AUTOSAR XML (schema 00050)
standard types defined: boolean, dtRef_const_VOID, dtRef_VOID, float32, sint16, sint8, uint16, uint32, uint64, uint8, boolean_CompuMethod, boolean_DataConstr, float32_DataConstr, sint16_DataConstr, sint8_DataConstr, uint16_DataConstr, uint8_DataConstr
package /ComponentTypes
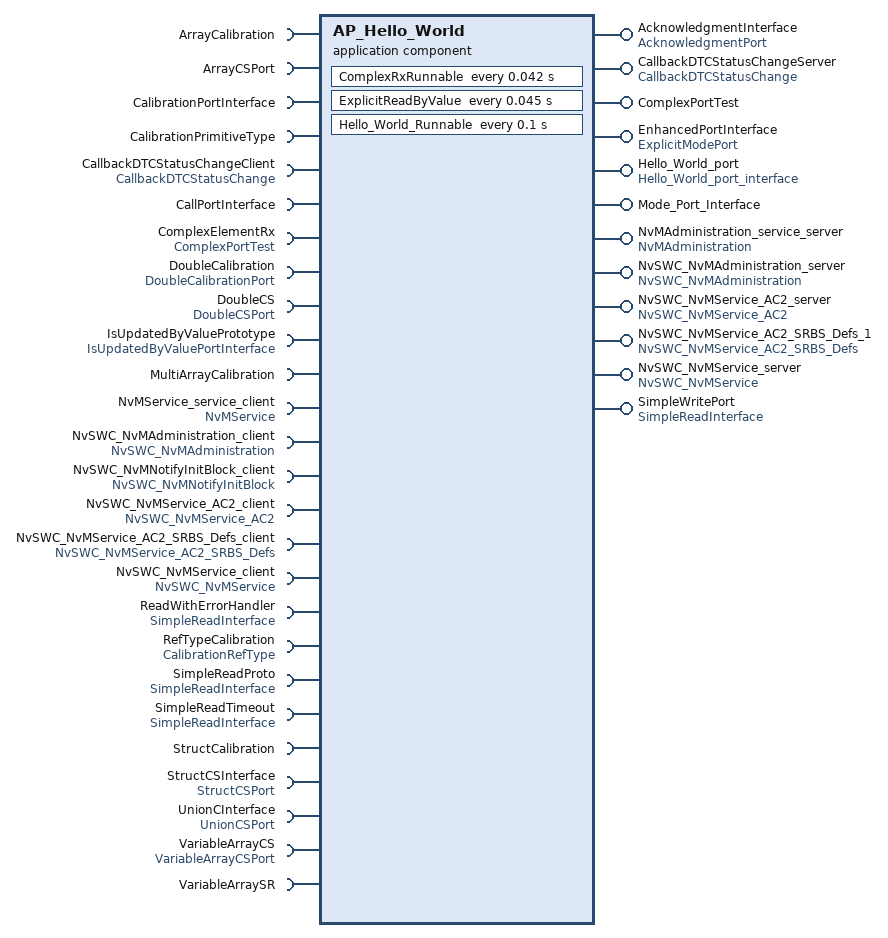
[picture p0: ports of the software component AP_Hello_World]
  application sw component type AP_Hello_World
    12 x provide port:
      AcknowledgmentInterface: provided-interface=AcknowledgmentPort
        provided-com-specs:
          data-element=nonWaitElement, transmission-acknowledge=timeout=0
          data-element=waitElement, transmission-acknowledge=timeout=0
      CallbackDTCStatusChangeServer: server-com-spec{operation=DTCStatusChanged, queue-length=1, end-to-end-transformation-com-spec-props=disable-end-to-end-check=false}, provided-interface=CallbackDTCStatusChange
      ComplexPortTest: provided-interface=ComplexPortTest
        provided-com-specs:
          queued-sender-com-spec={data-element=QueuedElement, transmission-acknowledge=timeout=2}
          nonqueued-sender-com-spec=data-element=ArrayOfTypeRefElement
          nonqueued-sender-com-spec={data-element=ComplexElement, transmission-acknowledge=timeout=2}
          nonqueued-sender-com-spec=data-element=ConstrainedElement
          nonqueued-sender-com-spec=data-element=HandleInvalidElement
      EnhancedPortInterface: mode-switch-sender-com-spec{enhanced-mode-api=true, mode-group=Mode, queue-length=1}, provided-interface=ExplicitModePort
      Hello_World_port: nonqueued-sender-com-spec{data-element=Hello_World_Element, init-value=0}, provided-interface=Hello_World_port_interface
      Mode_Port_Interface: mode-switch-sender-com-spec{enhanced-mode-api=false, mode-group=ModeGroup, mode-switched-ack=timeout=42, queue-length=123}, provided-interface=Mode_Port_Interface
      NvMAdministration_service_server: server-com-spec{operation=NvMAdministration/SetBlockProtection, queue-length=1}, provided-interface=NvMAdministration
      NvSWC_NvMAdministration_server: server-com-spec{operation=NvSWC_NvMAdministration/SetBlockProtection, queue-length=1}, provided-interface=NvSWC_NvMAdministration
      NvSWC_NvMService_AC2_server: provided-interface=NvSWC_NvMService_AC2
        provided-com-specs:
          operation=NvSWC_NvMService_AC2/GetErrorStatus, queue-length=1
          operation=NvSWC_NvMService_AC2/ReadBlock, queue-length=1
          operation=NvSWC_NvMService_AC2/WriteBlock, queue-length=10
      NvSWC_NvMService_AC2_SRBS_Defs_1: provided-interface=NvSWC_NvMService_AC2_SRBS_Defs
        provided-com-specs:
          operation=NvSWC_NvMService_AC2_SRBS_Defs/GetErrorStatus, queue-length=1
          operation=NvSWC_NvMService_AC2_SRBS_Defs/ReadBlock, queue-length=1
          operation=RestoreBlockDefaults, queue-length=1
          operation=SetRamBlockStatus, queue-length=1
          operation=NvSWC_NvMService_AC2_SRBS_Defs/WriteBlock, queue-length=1
      NvSWC_NvMService_server: server-com-spec{operation=NvSWC_NvMService/GetErrorStatus, queue-length=1}, provided-interface=NvSWC_NvMService
      SimpleWritePort: provided-interface=SimpleReadInterface
        provided-com-specs:
          data-element=ReadElementOpenRange
          data-element=ReadElementRangeInfMax
          data-element=SimpleReadElement
          data-element=SimpleReadNeverReceived
    10 x provide/require port:
      ArraySRInterface: provided-required-interface=ArraySRPort
        provided-com-specs:
          data-element=acknowlegdement, transmission-acknowledge=timeout=0
          data-element=constraint
          data-element=errorHandling
          data-element=handleKeep
          data-element=Iconstraint
          data-element=init, init-value=[0, 10, 20, 30, 40, 50, 60, 70, 80, 90]
          data-element=initConstraint, init-value=[1, 2, 3, 4, 5, 6, 7, 8, 9, 10]
          data-element=INone
        required-com-specs:
          data-element=acknowlegdement, filter=data-filter-type=ALWAYS
          data-element=constraint, filter=data-filter-type=ALWAYS
          data-element=errorHandling, filter=data-filter-type=ALWAYS
          data-element=handleKeep, filter=data-filter-type=ALWAYS
          data-element=Iconstraint, filter=data-filter-type=ALWAYS
          data-element=init, filter=data-filter-type=ALWAYS
          data-element=initConstraint, filter=data-filter-type=ALWAYS
          data-element=INone, filter=data-filter-type=ALWAYS
      BooleanSR: nonqueued-sender-com-spec=data-element=isElement, nonqueued-receiver-com-spec{data-element=isElement, filter=data-filter-type=ALWAYS}, provided-required-interface=BooleanSRPort
      DataConstraintInterface: provided-required-interface=DataConstraintPort
        provided-com-specs:
          data-element=AllConstr
          data-element=ApplicationTypeAllConstr
          data-element=ApplicationTypeConstr
          data-element=ApplicationTypeImplConstr
          data-element=DataProtypeApplConstr
          data-element=DataProtypeConstr
          data-element=DataProtypeImplConstr
          data-element=ImplementationTypeConstr
          data-element=InfFloatConstr
          data-element=NoConstr
        required-com-specs:
          data-element=AllConstr, filter=data-filter-type=ALWAYS
          data-element=ApplicationTypeAllConstr, filter=data-filter-type=ALWAYS
          data-element=ApplicationTypeConstr, filter=data-filter-type=ALWAYS
          data-element=ApplicationTypeImplConstr, filter=data-filter-type=ALWAYS
          data-element=DataProtypeApplConstr, filter=data-filter-type=ALWAYS
          data-element=DataProtypeConstr, filter=data-filter-type=ALWAYS
          data-element=DataProtypeImplConstr, filter=data-filter-type=ALWAYS
          data-element=ImplementationTypeConstr, filter=data-filter-type=ALWAYS
          data-element=InfFloatConstr
          data-element=NoConstr, filter=data-filter-type=ALWAYS
      DoubleSRPort: provided-com-specs=[data-element=DoubleSRPort/explicitElem, data-element=DoubleSRPort/implicitElem], provided-required-interface=DoubleSRPort
        required-com-specs:
          data-element=DoubleSRPort/explicitElem, filter=data-filter-type=ALWAYS
          data-element=DoubleSRPort/implicitElem, filter=data-filter-type=ALWAYS
      MultiArraySRInterface: provided-com-specs=[data-element=multiArray, data-element=multiArrayConstraint, data-element=multiArrayConstraintImplicit], provided-required-interface=MultiArraySRPort
        required-com-specs:
          data-element=multiArray, filter=data-filter-type=ALWAYS
          data-element=multiArrayConstraint, filter=data-filter-type=ALWAYS
          data-element=multiArrayConstraintImplicit, filter=data-filter-type=ALWAYS
      SimpleNvDataPort: nv-provide-com-spec=element_OneToTen, nv-require-com-spec=element_OneToTen, provided-required-interface=SimpleNvDataInterface
      StructSRInterface: provided-com-specs=[data-element=Element, data-element=IElement], provided-required-interface=StructSRPort
        required-com-specs:
          data-element=Element, filter=data-filter-type=ALWAYS
          data-element=IElement, filter=data-filter-type=ALWAYS
      TriggerInterface: provided-required-interface=SomeTriggerInterface
      TriggerInterfaceError: provided-required-interface=SomeTriggerInterface
      UnionSRInterface: provided-com-specs=[data-element=UnionSRPort/explicitElem, data-element=UnionSRPort/implicitElem], provided-required-interface=UnionSRPort
        required-com-specs:
          data-element=UnionSRPort/explicitElem, filter=data-filter-type=ALWAYS
          data-element=UnionSRPort/implicitElem, filter=data-filter-type=ALWAYS
    26 x require port:
      ArrayCalibration: required-com-specs=[arrayElement, variableArrayElem], required-interface=ArrayCalibration
      ArrayCSPort: required-com-specs=[ArrayCSPort/Operation, sumArray], required-interface=ArrayCSPort
      CalibrationPortInterface: parameter-require-com-spec{init-value=12342, parameter=CalibrationElement}, required-interface=CalibrationPortInterface
      CalibrationPrimitiveType: required-interface=CalibrationPrimitiveType
        required-com-specs:
          CalibrationPrimitiveType/notAccessibleElement
          CalibrationPrimitiveType/readOnlyElement
          CalibrationPrimitiveType/readWriteElement
      CallbackDTCStatusChangeClient: client-com-spec=DTCStatusChanged, required-interface=CallbackDTCStatusChange
      CallPortInterface: required-com-specs=[InOutOperation, SimpleIntOperation], required-interface=CallPortInterface
      ComplexElementRx: required-interface=ComplexPortTest
        required-com-specs:
          queued-receiver-com-spec={data-element=QueuedElement, queue-length=1}
          nonqueued-receiver-com-spec={data-element=ArrayOfTypeRefElement, filter=data-filter-type=ALWAYS, init-value=[rule-based-values={rule=FILL_UNTIL_END, rule-arguments=0}]}
          nonqueued-receiver-com-spec={data-element=ComplexElement, filter=data-filter-type=ALWAYS}
          nonqueued-receiver-com-spec={data-element=ConstrainedElement, filter=data-filter-type=ALWAYS}
          nonqueued-receiver-com-spec={data-element=HandleInvalidElement, filter=data-filter-type=ALWAYS}
      DoubleCalibration: parameter-require-com-spec=doubleElem, required-interface=DoubleCalibrationPort
      DoubleCS: client-com-spec=DoubleCSPort/f, required-interface=DoubleCSPort
      IsUpdatedByValuePrototype: required-interface=IsUpdatedByValuePortInterface
        required-com-specs:
          data-element=IdUpdatedByValueElement, enable-update=true, filter=data-filter-type=ALWAYS
          data-element=IsUpdatedByArgumentElement, enable-update=true, filter=data-filter-type=ALWAYS
      MultiArrayCalibration: parameter-require-com-spec=multiArrayElement, required-interface=MultiArrayCalibration
      NvMService_service_client: client-com-spec{operation=NvMService/GetErrorStatus, end-to-end-transformation-com-spec-props{disable-end-to-end-check=false, max-delta-counter=1, max-error-state-init=3, max-error-state-invalid=5, max-error-state-valid=7, max-no-new-or-repeated-data=9, min-ok-state-init=2, min-ok-state-invalid=4, min-ok-state-valid=6, sync-counter-init=8, window-size=10}}, required-interface=NvMService
      NvSWC_NvMAdministration_client: client-com-spec=NvSWC_NvMAdministration/SetBlockProtection, required-interface=NvSWC_NvMAdministration
      NvSWC_NvMNotifyInitBlock_client: client-com-spec=InitBlock, required-interface=NvSWC_NvMNotifyInitBlock
      NvSWC_NvMService_AC2_client: required-interface=NvSWC_NvMService_AC2
        required-com-specs:
          operation=NvSWC_NvMService_AC2/GetErrorStatus, end-to-end-transformation-com-spec-props=disable-end-to-end-check=true
          {operation=NvSWC_NvMService_AC2/ReadBlock, end-to-end-transformation-com-spec-props{disable-end-to-end-check=false, max-delta-counter=1, max-error-state-init=3, max-error-state-invalid=5, max-error-state-valid=7, max-no-new-or-repeated-data=9, min-ok-state-init=2, min-ok-state-invalid=4, min-ok-state-valid=6, sync-counter-init=8, window-size=10}}
          NvSWC_NvMService_AC2/WriteBlock
      NvSWC_NvMService_AC2_SRBS_Defs_client: required-interface=NvSWC_NvMService_AC2_SRBS_Defs
        required-com-specs:
          NvSWC_NvMService_AC2_SRBS_Defs/GetErrorStatus
          NvSWC_NvMService_AC2_SRBS_Defs/ReadBlock
          RestoreBlockDefaults
          SetRamBlockStatus
          NvSWC_NvMService_AC2_SRBS_Defs/WriteBlock
      NvSWC_NvMService_client: client-com-spec=NvSWC_NvMService/GetErrorStatus, required-interface=NvSWC_NvMService
      ReadWithErrorHandler: required-interface=SimpleReadInterface
        required-com-specs:
          data-element=ReadElementOpenRange, filter=data-filter-type=ALWAYS
          data-element=ReadElementRangeInfMax, filter=data-filter-type=ALWAYS
          data-element=SimpleReadElement, filter=data-filter-type=ALWAYS
          data-element=SimpleReadNeverReceived, filter=data-filter-type=ALWAYS
      RefTypeCalibration: required-interface=CalibrationRefType
        required-com-specs:
          CalibrationRefType/notAccessibleElement
          CalibrationRefType/readOnlyElement
          CalibrationRefType/readWriteElement
      SimpleReadProto: required-interface=SimpleReadInterface
        required-com-specs:
          data-element=ReadElementOpenRange, filter=data-filter-type=ALWAYS
          data-element=ReadElementRangeInfMax, filter=data-filter-type=ALWAYS
          data-element=SimpleReadElement, filter=data-filter-type=ALWAYS, handle-never-received=true, init-value=12345
          data-element=SimpleReadNeverReceived, filter=data-filter-type=ALWAYS, handle-never-received=true
      SimpleReadTimeout: required-interface=SimpleReadInterface
        required-com-specs:
          data-element=ReadElementOpenRange, filter=data-filter-type=ALWAYS
          data-element=ReadElementRangeInfMax, filter=data-filter-type=ALWAYS
          data-element=SimpleReadElement, alive-timeout=3, filter=data-filter-type=ALWAYS
          data-element=SimpleReadNeverReceived, filter=data-filter-type=ALWAYS
      StructCalibration: parameter-require-com-spec=Element, required-interface=StructCalibration
      StructCSInterface: required-com-specs=[cloneStruct, StructCSPort/Operation], required-interface=StructCSPort
      UnionCInterface: client-com-spec=UnionCSPort/f, required-interface=UnionCSPort
      VariableArrayCS: client-com-spec=VariableArrayCSPort/f, required-interface=VariableArrayCSPort
      VariableArraySR: queued-receiver-com-spec{data-element=variableArrayConstr, queue-length=1}, required-interface=VariableArraySR
    behavior AP_Hello_World_InternalBehavior: data-type-mapping=[RecordMapping, CustomMap]
      exclusive area TestExclusiveArea
      ar-typed-per-instance-memorys:
        data PerInstanceMemory: sw-calibration-access=READ-ONLY, type=uint16
      data send completed event Event_WAIT_LOCAL_AcknowledgmentInterface_waitElement_SEND_AcknowledgmentInterface_waitElement: event-source=SEND_AcknowledgmentInterface_waitElement
      asynchronous server call returns event ASCRE_Hello_World_Runnable_AC_NvSWC_NvMService_client_GetErrorStatus: event-source=ASCRP_Hello_World_Runnable_AC_NvSWC_NvMService_client_GetErrorStatus
      mode switched ack event a9a433f4D5e4fD45a1Db829D577591972cd1: event-source=SWITCH_Mode_Port_Interface_ModeGroup
      4 x asynchronous server call returns event:
        ASCRE_NvSWC_NvMService_client_GetErrorStatus: event-source=ASCRP_NvSWC_NvMService_client_GetErrorStatus
        ASCRE_ServerCallRunnable_SC_NvSWC_NvMAdministration_client_SetBlockProtection: event-source=ASCRP_ServerCallRunnable_SC_NvSWC_NvMAdministration_client_SetBlockProtection
        ASCRE_ServiceRunnable_AC_NvSWC_NvMService_AC2_SRBS_Defs_client_SetRamBlockStatus: event-source=ASCRP_ServiceRunnable_AC_NvSWC_NvMService_AC2_SRBS_Defs_client_SetRamBlockStatus
        ASCRE_ServiceRunnable_SC_CallPortInterface_OtherIntOperation: event-source=ASCRP_ServiceRunnable_SC_CallPortInterface_OtherIntOperation
      timing event TMT_ComplexRxRunnable: start-on-event=ComplexRxRunnable, period=0.042
      timing event TMT_Runnable: start-on-event=ExplicitReadByValue, period=0.045
      timing event TMT_Hello_World_Runnable: start-on-event=Hello_World_Runnable, period=0.1
      external trigger occurred event EXTO_Hello_World_Runnable_TriggerInterface_SomeTriggerElement: start-on-event=Hello_World_Runnable, trigger=TriggerInterface.SomeTriggerElement
      external trigger occurred event EXTO_Hello_World_Runnable_TriggerInterfaceError_SomeTriggerElement: start-on-event=Hello_World_Runnable, trigger=TriggerInterfaceError.SomeTriggerElement
      4 x timing event:
        TMT_ImplicitReadRunnable: start-on-event=ImplicitReadRunnable, period=0.123
        TMT_0_MultipleInstanciationRunnable: start-on-event=MultipleInstanciationRunnable, period=0.132
        TMT_ReceiveRecordRunnable: start-on-event=ReceiveRecordRunnable, period=0.01
        TMT_ServerCallRunnable: start-on-event=ServiceRunnable, period=0.042
      explicit-inter-runnable-variables:
        data ExplicitInterRunnableStruct: type=ComplexStruct, init-value=fields=[intElement:0, floatElement:0, arrayElement:10 x 0, {short-label=structElement, fields=[boolElement:0, constrElement:0]}]
        data ExplicitInterRunnableValue: type=Uint8Constr, init-value=0
      implicit-inter-runnable-variables:
        data ImplicitInterRunnableStruct: type=ComplexStruct, init-value=fields=[intElement:0, floatElement:0, arrayElement:10 x 0, {short-label=structElement, fields=[boolElement:0, constrElement:0]}]
        data ImplicitInterRunnableValue: type=Uint8Constr, init-value=0
      per-instance-parameters:
        parameter data prototype PerInstanceInternalCalibrationParameter: sw-calibration-access=READ-ONLY, type=Uint8Constr
      port-api-options:
        enable-take-address=false, error-handling=NO-TRANSFORMER-ERROR-HANDLING, indirect-api=false, port=ArraySRInterface
        enable-take-address=false, error-handling=NO-TRANSFORMER-ERROR-HANDLING, indirect-api=false, port=CalibrationPortInterface
        enable-take-address=true, error-handling=NO-TRANSFORMER-ERROR-HANDLING, indirect-api=false, port=ComplexElementRx
        enable-take-address=false, error-handling=TRANSFORMER-ERROR-HANDLING, indirect-api=false, port=ComplexPortTest
        enable-take-address=false, error-handling=TRANSFORMER-ERROR-HANDLING, indirect-api=false, port=Hello_World_port
        enable-take-address=false, error-handling=NO-TRANSFORMER-ERROR-HANDLING, indirect-api=false, port=IsUpdatedByValuePrototype
        enable-take-address=false, error-handling=TRANSFORMER-ERROR-HANDLING, indirect-api=false, port=NvSWC_NvMNotifyInitBlock_client
        enable-take-address=false, error-handling=TRANSFORMER-ERROR-HANDLING, indirect-api=false, port=NvSWC_NvMService_AC2_client
        enable-take-address=false, error-handling=TRANSFORMER-ERROR-HANDLING, indirect-api=false, port=NvSWC_NvMService_AC2_SRBS_Defs_client
        enable-take-address=false, error-handling=NO-TRANSFORMER-ERROR-HANDLING, indirect-api=false, port=ReadWithErrorHandler
        enable-take-address=false, error-handling=NO-TRANSFORMER-ERROR-HANDLING, indirect-api=false, port=SimpleReadProto
        enable-take-address=false, error-handling=NO-TRANSFORMER-ERROR-HANDLING, indirect-api=false, port=SimpleWritePort
        enable-take-address=false, error-handling=TRANSFORMER-ERROR-HANDLING, indirect-api=false, port=TriggerInterfaceError
      22 x runnable:
        ArrayRunnable
          data-read-access:
            access READ_ArraySRInterface_Iconstraint: accessed-variable=ArraySRInterface.Iconstraint
            access READ_ArraySRInterface_INone: accessed-variable=ArraySRInterface.INone
          data-receive-point-by-arguments:
            6 x access:
              REC_ArraySRInterface_acknowlegdement: accessed-variable=ArraySRInterface.acknowlegdement
              REC_ArraySRInterface_constraint: accessed-variable=ArraySRInterface.constraint
              REC_ArraySRInterface_errorHandling: accessed-variable=ArraySRInterface.errorHandling
              REC_ArraySRInterface_handleKeep: accessed-variable=ArraySRInterface.handleKeep
              REC_ArraySRInterface_init: accessed-variable=ArraySRInterface.init
              REC_ArraySRInterface_initConstraint: accessed-variable=ArraySRInterface.initConstraint
          data-send-points:
            6 x access:
              SEND_ArraySRInterface_acknowlegdement: accessed-variable=ArraySRInterface.acknowlegdement
              SEND_ArraySRInterface_constraint: accessed-variable=ArraySRInterface.constraint
              SEND_ArraySRInterface_errorHandling: accessed-variable=ArraySRInterface.errorHandling
              SEND_ArraySRInterface_handleKeep: accessed-variable=ArraySRInterface.handleKeep
              SEND_ArraySRInterface_init: accessed-variable=ArraySRInterface.init
              SEND_ArraySRInterface_initConstraint: accessed-variable=ArraySRInterface.initConstraint
          data-write-access:
            access WRITE_ArraySRInterface_Iconstraint: accessed-variable=ArraySRInterface.Iconstraint
            access WRITE_ArraySRInterface_INone: accessed-variable=ArraySRInterface.INone
          14 x parameter access:
            PA_ArrayCalibration_arrayElement: accessed-parameter=ArrayCalibration.arrayElement
            PA_ArrayCalibration_variableArrayElem: accessed-parameter=ArrayCalibration.variableArrayElem
            PA_CalibrationPortInterface_CalibrationElement: accessed-parameter=CalibrationPortInterface.CalibrationElement
            PA_CalibrationPrimitiveType_notAccessibleElement: accessed-parameter=CalibrationPrimitiveType.notAccessibleElement
            PA_CalibrationPrimitiveType_readOnlyElement: accessed-parameter=CalibrationPrimitiveType.readOnlyElement
            PA_CalibrationPrimitiveType_readWriteElement: accessed-parameter=CalibrationPrimitiveType.readWriteElement
            PA_DoubleCalibration_doubleElem: accessed-parameter=DoubleCalibration.doubleElem
            PA_MultiArrayCalibration_multiArrayElement: accessed-parameter=MultiArrayCalibration.multiArrayElement
            PA_PerInstanceInternalCalibrationParameter: accessed-parameter=PerInstanceInternalCalibrationParameter
            PA_RefTypeCalibration_notAccessibleElement: accessed-parameter=RefTypeCalibration.notAccessibleElement
            PA_RefTypeCalibration_readOnlyElement: accessed-parameter=RefTypeCalibration.readOnlyElement
            PA_RefTypeCalibration_readWriteElement: accessed-parameter=RefTypeCalibration.readWriteElement
            PA_SharedInternalCalibrationParameter: accessed-parameter=SharedInternalCalibrationParameter
            PA_StructCalibration_Element: accessed-parameter=StructCalibration.Element
          sync call SC_ArrayCSPort_sumArray: operation=ArrayCSPort.sumArray, timeout=0
        BooleanRunnable
          data-receive-point-by-arguments:
            access REC_BooleanSR_isElement: accessed-variable=BooleanSR.isElement
          14 x parameter access:
            PA_ArrayCalibration_arrayElement: accessed-parameter=ArrayCalibration.arrayElement
            PA_ArrayCalibration_variableArrayElem: accessed-parameter=ArrayCalibration.variableArrayElem
            PA_CalibrationPortInterface_CalibrationElement: accessed-parameter=CalibrationPortInterface.CalibrationElement
            PA_CalibrationPrimitiveType_notAccessibleElement: accessed-parameter=CalibrationPrimitiveType.notAccessibleElement
            PA_CalibrationPrimitiveType_readOnlyElement: accessed-parameter=CalibrationPrimitiveType.readOnlyElement
            PA_CalibrationPrimitiveType_readWriteElement: accessed-parameter=CalibrationPrimitiveType.readWriteElement
            PA_DoubleCalibration_doubleElem: accessed-parameter=DoubleCalibration.doubleElem
            PA_MultiArrayCalibration_multiArrayElement: accessed-parameter=MultiArrayCalibration.multiArrayElement
            PA_PerInstanceInternalCalibrationParameter: accessed-parameter=PerInstanceInternalCalibrationParameter
            PA_RefTypeCalibration_notAccessibleElement: accessed-parameter=RefTypeCalibration.notAccessibleElement
            PA_RefTypeCalibration_readOnlyElement: accessed-parameter=RefTypeCalibration.readOnlyElement
            PA_RefTypeCalibration_readWriteElement: accessed-parameter=RefTypeCalibration.readWriteElement
            PA_SharedInternalCalibrationParameter: accessed-parameter=SharedInternalCalibrationParameter
            PA_StructCalibration_Element: accessed-parameter=StructCalibration.Element
        ComplexArrayRunnable
          data-read-access:
            access READ_MultiArraySRInterface_multiArrayConstraintImplicit: accessed-variable=MultiArraySRInterface.multiArrayConstraintImplicit
          data-receive-point-by-arguments:
            access REC_MultiArraySRInterface_multiArray: accessed-variable=MultiArraySRInterface.multiArray
            access REC_MultiArraySRInterface_multiArrayConstraint: accessed-variable=MultiArraySRInterface.multiArrayConstraint
          data-send-points:
            access SEND_MultiArraySRInterface_multiArray: accessed-variable=MultiArraySRInterface.multiArray
            access SEND_MultiArraySRInterface_multiArrayConstraint: accessed-variable=MultiArraySRInterface.multiArrayConstraint
          data-write-access:
            access WRITE_MultiArraySRInterface_multiArrayConstraintImplicit: accessed-variable=MultiArraySRInterface.multiArrayConstraintImplicit
          14 x parameter access:
            PA_ArrayCalibration_arrayElement: accessed-parameter=ArrayCalibration.arrayElement
            PA_ArrayCalibration_variableArrayElem: accessed-parameter=ArrayCalibration.variableArrayElem
            PA_CalibrationPortInterface_CalibrationElement: accessed-parameter=CalibrationPortInterface.CalibrationElement
            PA_CalibrationPrimitiveType_notAccessibleElement: accessed-parameter=CalibrationPrimitiveType.notAccessibleElement
            PA_CalibrationPrimitiveType_readOnlyElement: accessed-parameter=CalibrationPrimitiveType.readOnlyElement
            PA_CalibrationPrimitiveType_readWriteElement: accessed-parameter=CalibrationPrimitiveType.readWriteElement
            PA_DoubleCalibration_doubleElem: accessed-parameter=DoubleCalibration.doubleElem
            PA_MultiArrayCalibration_multiArrayElement: accessed-parameter=MultiArrayCalibration.multiArrayElement
            PA_PerInstanceInternalCalibrationParameter: accessed-parameter=PerInstanceInternalCalibrationParameter
            PA_RefTypeCalibration_notAccessibleElement: accessed-parameter=RefTypeCalibration.notAccessibleElement
            PA_RefTypeCalibration_readOnlyElement: accessed-parameter=RefTypeCalibration.readOnlyElement
            PA_RefTypeCalibration_readWriteElement: accessed-parameter=RefTypeCalibration.readWriteElement
            PA_SharedInternalCalibrationParameter: accessed-parameter=SharedInternalCalibrationParameter
            PA_StructCalibration_Element: accessed-parameter=StructCalibration.Element
        ComplexRxRunnable
          data-receive-point-by-arguments:
            4 x access:
              REC_ComplexElementRx_ComplexElement: accessed-variable=ComplexElementRx.ComplexElement
              REC_ComplexElementRx_ConstrainedElement: accessed-variable=ComplexElementRx.ConstrainedElement
              REC_ComplexElementRx_HandleInvalidElement: accessed-variable=ComplexElementRx.HandleInvalidElement
              REC_ComplexElementRx_QueuedElement: accessed-variable=ComplexElementRx.QueuedElement
          14 x parameter access:
            PA_ArrayCalibration_arrayElement: accessed-parameter=ArrayCalibration.arrayElement
            PA_ArrayCalibration_variableArrayElem: accessed-parameter=ArrayCalibration.variableArrayElem
            PA_CalibrationPortInterface_CalibrationElement: accessed-parameter=CalibrationPortInterface.CalibrationElement
            PA_CalibrationPrimitiveType_notAccessibleElement: accessed-parameter=CalibrationPrimitiveType.notAccessibleElement
            PA_CalibrationPrimitiveType_readOnlyElement: accessed-parameter=CalibrationPrimitiveType.readOnlyElement
            PA_CalibrationPrimitiveType_readWriteElement: accessed-parameter=CalibrationPrimitiveType.readWriteElement
            PA_DoubleCalibration_doubleElem: accessed-parameter=DoubleCalibration.doubleElem
            PA_MultiArrayCalibration_multiArrayElement: accessed-parameter=MultiArrayCalibration.multiArrayElement
            PA_PerInstanceInternalCalibrationParameter: accessed-parameter=PerInstanceInternalCalibrationParameter
            PA_RefTypeCalibration_notAccessibleElement: accessed-parameter=RefTypeCalibration.notAccessibleElement
            PA_RefTypeCalibration_readOnlyElement: accessed-parameter=RefTypeCalibration.readOnlyElement
            PA_RefTypeCalibration_readWriteElement: accessed-parameter=RefTypeCalibration.readWriteElement
            PA_SharedInternalCalibrationParameter: accessed-parameter=SharedInternalCalibrationParameter
            PA_StructCalibration_Element: accessed-parameter=StructCalibration.Element
        DataConstraintRunnable
          data-receive-point-by-arguments:
            10 x access:
              REC_DataConstraintInterface_AllConstr: accessed-variable=DataConstraintInterface.AllConstr
              REC_DataConstraintInterface_ApplicationTypeAllConstr: accessed-variable=DataConstraintInterface.ApplicationTypeAllConstr
              REC_DataConstraintInterface_ApplicationTypeConstr: accessed-variable=DataConstraintInterface.ApplicationTypeConstr
              REC_DataConstraintInterface_ApplicationTypeImplConstr: accessed-variable=DataConstraintInterface.ApplicationTypeImplConstr
              REC_DataConstraintInterface_DataProtypeApplConstr: accessed-variable=DataConstraintInterface.DataProtypeApplConstr
              REC_DataConstraintInterface_DataProtypeConstr: accessed-variable=DataConstraintInterface.DataProtypeConstr
              REC_DataConstraintInterface_DataProtypeImplConstr: accessed-variable=DataConstraintInterface.DataProtypeImplConstr
              REC_DataConstraintInterface_ImplementationTypeConstr: accessed-variable=DataConstraintInterface.ImplementationTypeConstr
              REC_DataConstraintInterface_InfFloatConstr: accessed-variable=DataConstraintInterface.InfFloatConstr
              REC_DataConstraintInterface_NoConstr: accessed-variable=DataConstraintInterface.NoConstr
          data-send-points:
            9 x access:
              SEND_DataConstraintInterface_AllConstr: accessed-variable=DataConstraintInterface.AllConstr
              SEND_DataConstraintInterface_ApplicationTypeAllConstr: accessed-variable=DataConstraintInterface.ApplicationTypeAllConstr
              SEND_DataConstraintInterface_ApplicationTypeConstr: accessed-variable=DataConstraintInterface.ApplicationTypeConstr
              SEND_DataConstraintInterface_ApplicationTypeImplConstr: accessed-variable=DataConstraintInterface.ApplicationTypeImplConstr
              SEND_DataConstraintInterface_DataProtypeApplConstr: accessed-variable=DataConstraintInterface.DataProtypeApplConstr
              SEND_DataConstraintInterface_DataProtypeConstr: accessed-variable=DataConstraintInterface.DataProtypeConstr
              SEND_DataConstraintInterface_DataProtypeImplConstr: accessed-variable=DataConstraintInterface.DataProtypeImplConstr
              SEND_DataConstraintInterface_ImplementationTypeConstr: accessed-variable=DataConstraintInterface.ImplementationTypeConstr
              SEND_DataConstraintInterface_NoConstr: accessed-variable=DataConstraintInterface.NoConstr
          14 x parameter access:
            PA_ArrayCalibration_arrayElement: accessed-parameter=ArrayCalibration.arrayElement
            PA_ArrayCalibration_variableArrayElem: accessed-parameter=ArrayCalibration.variableArrayElem
            PA_CalibrationPortInterface_CalibrationElement: accessed-parameter=CalibrationPortInterface.CalibrationElement
            PA_CalibrationPrimitiveType_notAccessibleElement: accessed-parameter=CalibrationPrimitiveType.notAccessibleElement
            PA_CalibrationPrimitiveType_readOnlyElement: accessed-parameter=CalibrationPrimitiveType.readOnlyElement
            PA_CalibrationPrimitiveType_readWriteElement: accessed-parameter=CalibrationPrimitiveType.readWriteElement
            PA_DoubleCalibration_doubleElem: accessed-parameter=DoubleCalibration.doubleElem
            PA_MultiArrayCalibration_multiArrayElement: accessed-parameter=MultiArrayCalibration.multiArrayElement
            PA_PerInstanceInternalCalibrationParameter: accessed-parameter=PerInstanceInternalCalibrationParameter
            PA_RefTypeCalibration_notAccessibleElement: accessed-parameter=RefTypeCalibration.notAccessibleElement
            PA_RefTypeCalibration_readOnlyElement: accessed-parameter=RefTypeCalibration.readOnlyElement
            PA_RefTypeCalibration_readWriteElement: accessed-parameter=RefTypeCalibration.readWriteElement
            PA_SharedInternalCalibrationParameter: accessed-parameter=SharedInternalCalibrationParameter
            PA_StructCalibration_Element: accessed-parameter=StructCalibration.Element
        DoubleRunnable
          data-read-access:
            access REC_DoubleSRPort_implicitElem: accessed-variable=DoubleSRPort.implicitElem
          data-receive-point-by-arguments:
            access REC_DoubleSRPort_explicitElem: accessed-variable=DoubleSRPort.explicitElem
          data-send-points:
            access SEND_DoubleSRPort_explicitElem: accessed-variable=DoubleSRPort.explicitElem
          data-write-access:
            access SEND_DoubleSRPort_implicitElem: accessed-variable=DoubleSRPort.implicitElem
          14 x parameter access:
            PA_ArrayCalibration_arrayElement: accessed-parameter=ArrayCalibration.arrayElement
            PA_ArrayCalibration_variableArrayElem: accessed-parameter=ArrayCalibration.variableArrayElem
            PA_CalibrationPortInterface_CalibrationElement: accessed-parameter=CalibrationPortInterface.CalibrationElement
            PA_CalibrationPrimitiveType_notAccessibleElement: accessed-parameter=CalibrationPrimitiveType.notAccessibleElement
            PA_CalibrationPrimitiveType_readOnlyElement: accessed-parameter=CalibrationPrimitiveType.readOnlyElement
            PA_CalibrationPrimitiveType_readWriteElement: accessed-parameter=CalibrationPrimitiveType.readWriteElement
            PA_DoubleCalibration_doubleElem: accessed-parameter=DoubleCalibration.doubleElem
            PA_MultiArrayCalibration_multiArrayElement: accessed-parameter=MultiArrayCalibration.multiArrayElement
            PA_PerInstanceInternalCalibrationParameter: accessed-parameter=PerInstanceInternalCalibrationParameter
            PA_RefTypeCalibration_notAccessibleElement: accessed-parameter=RefTypeCalibration.notAccessibleElement
            PA_RefTypeCalibration_readOnlyElement: accessed-parameter=RefTypeCalibration.readOnlyElement
            PA_RefTypeCalibration_readWriteElement: accessed-parameter=RefTypeCalibration.readWriteElement
            PA_SharedInternalCalibrationParameter: accessed-parameter=SharedInternalCalibrationParameter
            PA_StructCalibration_Element: accessed-parameter=StructCalibration.Element
          sync call SC_DoubleCS_f: operation=DoubleCS.f, timeout=0
        DReadRunnable
          data-receive-point-by-values:
            access REC_ReadWithErrorHandler_ReadElementOpenRange: accessed-variable=ReadWithErrorHandler.ReadElementOpenRange
            access REC_SimpleNvDataPort_element_OneToTen: accessed-variable=SimpleNvDataPort.element_OneToTen
            access REC_SimpleReadTimeout_ReadElementOpenRange: accessed-variable=SimpleReadTimeout.ReadElementOpenRange
          14 x parameter access:
            PA_ArrayCalibration_arrayElement: accessed-parameter=ArrayCalibration.arrayElement
            PA_ArrayCalibration_variableArrayElem: accessed-parameter=ArrayCalibration.variableArrayElem
            PA_CalibrationPortInterface_CalibrationElement: accessed-parameter=CalibrationPortInterface.CalibrationElement
            PA_CalibrationPrimitiveType_notAccessibleElement: accessed-parameter=CalibrationPrimitiveType.notAccessibleElement
            PA_CalibrationPrimitiveType_readOnlyElement: accessed-parameter=CalibrationPrimitiveType.readOnlyElement
            PA_CalibrationPrimitiveType_readWriteElement: accessed-parameter=CalibrationPrimitiveType.readWriteElement
            PA_DoubleCalibration_doubleElem: accessed-parameter=DoubleCalibration.doubleElem
            PA_MultiArrayCalibration_multiArrayElement: accessed-parameter=MultiArrayCalibration.multiArrayElement
            PA_PerInstanceInternalCalibrationParameter: accessed-parameter=PerInstanceInternalCalibrationParameter
            PA_RefTypeCalibration_notAccessibleElement: accessed-parameter=RefTypeCalibration.notAccessibleElement
            PA_RefTypeCalibration_readOnlyElement: accessed-parameter=RefTypeCalibration.readOnlyElement
            PA_RefTypeCalibration_readWriteElement: accessed-parameter=RefTypeCalibration.readWriteElement
            PA_SharedInternalCalibrationParameter: accessed-parameter=SharedInternalCalibrationParameter
            PA_StructCalibration_Element: accessed-parameter=StructCalibration.Element
        DTCServiceRunnable
          14 x parameter access:
            PA_ArrayCalibration_arrayElement: accessed-parameter=ArrayCalibration.arrayElement
            PA_ArrayCalibration_variableArrayElem: accessed-parameter=ArrayCalibration.variableArrayElem
            PA_CalibrationPortInterface_CalibrationElement: accessed-parameter=CalibrationPortInterface.CalibrationElement
            PA_CalibrationPrimitiveType_notAccessibleElement: accessed-parameter=CalibrationPrimitiveType.notAccessibleElement
            PA_CalibrationPrimitiveType_readOnlyElement: accessed-parameter=CalibrationPrimitiveType.readOnlyElement
            PA_CalibrationPrimitiveType_readWriteElement: accessed-parameter=CalibrationPrimitiveType.readWriteElement
            PA_DoubleCalibration_doubleElem: accessed-parameter=DoubleCalibration.doubleElem
            PA_MultiArrayCalibration_multiArrayElement: accessed-parameter=MultiArrayCalibration.multiArrayElement
            PA_PerInstanceInternalCalibrationParameter: accessed-parameter=PerInstanceInternalCalibrationParameter
            PA_RefTypeCalibration_notAccessibleElement: accessed-parameter=RefTypeCalibration.notAccessibleElement
            PA_RefTypeCalibration_readOnlyElement: accessed-parameter=RefTypeCalibration.readOnlyElement
            PA_RefTypeCalibration_readWriteElement: accessed-parameter=RefTypeCalibration.readWriteElement
            PA_SharedInternalCalibrationParameter: accessed-parameter=SharedInternalCalibrationParameter
            PA_StructCalibration_Element: accessed-parameter=StructCalibration.Element
        ExplicitReadByValue
          data-receive-point-by-arguments:
            6 x access:
              READ_SimpleReadTimeout_SimpleReadElement: accessed-variable=SimpleReadTimeout.SimpleReadElement
              REC_hello_receiver_1_hello_reciever_element: accessed-variable=SimpleReadProto.SimpleReadElement
              REC_ReadWithErrorHandler_SimpleReadElement: accessed-variable=ReadWithErrorHandler.SimpleReadElement
              REC_SimpleReadProto_ReadElementOpenRange: accessed-variable=SimpleReadProto.ReadElementOpenRange
              REC_SimpleReadProto_ReadElementRangeInfMax: accessed-variable=SimpleReadProto.ReadElementRangeInfMax
              REC_SimpleReadTimeout_SimpleReadNeverReceived: accessed-variable=SimpleReadTimeout.SimpleReadNeverReceived
          14 x parameter access:
            PA_ArrayCalibration_arrayElement: accessed-parameter=ArrayCalibration.arrayElement
            PA_ArrayCalibration_variableArrayElem: accessed-parameter=ArrayCalibration.variableArrayElem
            PA_CalibrationPortInterface_CalibrationElement: accessed-parameter=CalibrationPortInterface.CalibrationElement
            PA_CalibrationPrimitiveType_notAccessibleElement: accessed-parameter=CalibrationPrimitiveType.notAccessibleElement
            PA_CalibrationPrimitiveType_readOnlyElement: accessed-parameter=CalibrationPrimitiveType.readOnlyElement
            PA_CalibrationPrimitiveType_readWriteElement: accessed-parameter=CalibrationPrimitiveType.readWriteElement
            PA_DoubleCalibration_doubleElem: accessed-parameter=DoubleCalibration.doubleElem
            PA_MultiArrayCalibration_multiArrayElement: accessed-parameter=MultiArrayCalibration.multiArrayElement
            PA_PerInstanceInternalCalibrationParameter: accessed-parameter=PerInstanceInternalCalibrationParameter
            PA_RefTypeCalibration_notAccessibleElement: accessed-parameter=RefTypeCalibration.notAccessibleElement
            PA_RefTypeCalibration_readOnlyElement: accessed-parameter=RefTypeCalibration.readOnlyElement
            PA_RefTypeCalibration_readWriteElement: accessed-parameter=RefTypeCalibration.readWriteElement
            PA_SharedInternalCalibrationParameter: accessed-parameter=SharedInternalCalibrationParameter
            PA_StructCalibration_Element: accessed-parameter=StructCalibration.Element
        FeedbackRunnable
          data-send-points:
            access SEND_AcknowledgmentInterface_nonWaitElement: accessed-variable=AcknowledgmentInterface.nonWaitElement
            access SEND_AcknowledgmentInterface_waitElement: accessed-variable=AcknowledgmentInterface.waitElement
          14 x parameter access:
            PA_ArrayCalibration_arrayElement: accessed-parameter=ArrayCalibration.arrayElement
            PA_ArrayCalibration_variableArrayElem: accessed-parameter=ArrayCalibration.variableArrayElem
            PA_CalibrationPortInterface_CalibrationElement: accessed-parameter=CalibrationPortInterface.CalibrationElement
            PA_CalibrationPrimitiveType_notAccessibleElement: accessed-parameter=CalibrationPrimitiveType.notAccessibleElement
            PA_CalibrationPrimitiveType_readOnlyElement: accessed-parameter=CalibrationPrimitiveType.readOnlyElement
            PA_CalibrationPrimitiveType_readWriteElement: accessed-parameter=CalibrationPrimitiveType.readWriteElement
            PA_DoubleCalibration_doubleElem: accessed-parameter=DoubleCalibration.doubleElem
            PA_MultiArrayCalibration_multiArrayElement: accessed-parameter=MultiArrayCalibration.multiArrayElement
            PA_PerInstanceInternalCalibrationParameter: accessed-parameter=PerInstanceInternalCalibrationParameter
            PA_RefTypeCalibration_notAccessibleElement: accessed-parameter=RefTypeCalibration.notAccessibleElement
            PA_RefTypeCalibration_readOnlyElement: accessed-parameter=RefTypeCalibration.readOnlyElement
            PA_RefTypeCalibration_readWriteElement: accessed-parameter=RefTypeCalibration.readWriteElement
            PA_SharedInternalCalibrationParameter: accessed-parameter=SharedInternalCalibrationParameter
            PA_StructCalibration_Element: accessed-parameter=StructCalibration.Element
          wait point WAIT_LOCAL_AcknowledgmentInterface_waitElement_SEND_AcknowledgmentInterface_waitElement: timeout=0, trigger=Event_WAIT_LOCAL_AcknowledgmentInterface_waitElement_SEND_AcknowledgmentInterface_waitElement
        Hello_World_Runnable: can-enter-exclusive-area=TestExclusiveArea, external-triggering-point=TriggerInterface.SomeTriggerElement
          asynchronous server call result point ASCRP_Hello_World_Runnable_AC_NvSWC_NvMService_client_GetErrorStatus: asynchronous-server-call-point=AC_NvSWC_NvMService_client_GetErrorStatus
          data-send-points:
            access SEND_ComplexPortTest_QueuedElement: accessed-variable=ComplexPortTest.QueuedElement
            access SEND_Hello_World_port_interface_Hello_World_Element: accessed-variable=Hello_World_port.Hello_World_Element
          mode switch point SWITCH_Mode_Port_Interface_ModeGroup: mode-group=Mode_Port_Interface.ModeGroup
          14 x parameter access:
            PA_ArrayCalibration_arrayElement: accessed-parameter=ArrayCalibration.arrayElement
            PA_ArrayCalibration_variableArrayElem: accessed-parameter=ArrayCalibration.variableArrayElem
            PA_CalibrationPortInterface_CalibrationElement: accessed-parameter=CalibrationPortInterface.CalibrationElement
            PA_CalibrationPrimitiveType_notAccessibleElement: accessed-parameter=CalibrationPrimitiveType.notAccessibleElement
            PA_CalibrationPrimitiveType_readOnlyElement: accessed-parameter=CalibrationPrimitiveType.readOnlyElement
            PA_CalibrationPrimitiveType_readWriteElement: accessed-parameter=CalibrationPrimitiveType.readWriteElement
            PA_DoubleCalibration_doubleElem: accessed-parameter=DoubleCalibration.doubleElem
            PA_MultiArrayCalibration_multiArrayElement: accessed-parameter=MultiArrayCalibration.multiArrayElement
            PA_PerInstanceInternalCalibrationParameter: accessed-parameter=PerInstanceInternalCalibrationParameter
            PA_RefTypeCalibration_notAccessibleElement: accessed-parameter=RefTypeCalibration.notAccessibleElement
            PA_RefTypeCalibration_readOnlyElement: accessed-parameter=RefTypeCalibration.readOnlyElement
            PA_RefTypeCalibration_readWriteElement: accessed-parameter=RefTypeCalibration.readWriteElement
            PA_SharedInternalCalibrationParameter: accessed-parameter=SharedInternalCalibrationParameter
            PA_StructCalibration_Element: accessed-parameter=StructCalibration.Element
          async call AC_NvSWC_NvMService_client_GetErrorStatus: operation=NvSWC_NvMService_client.GetErrorStatus, timeout=0
          wait point WAIT_SWITCH_Mode_Port_Interface_ModeGroup: trigger=a9a433f4D5e4fD45a1Db829D577591972cd1
          wait point WP_Hello_World_Runnable_AC_NvSWC_NvMService_client_GetErrorStatus: timeout=0, trigger=ASCRE_Hello_World_Runnable_AC_NvSWC_NvMService_client_GetErrorStatus
        ImpliciteWrite
          data-write-access:
            7 x access:
              WRITE_ComplexPortTest_ComplexElement: accessed-variable=ComplexPortTest.ComplexElement
              WRITE_ComplexPortTest_ConstrainedElement: accessed-variable=ComplexPortTest.ConstrainedElement
              WRITE_ComplexPortTest_HandleInvalidElement: accessed-variable=ComplexPortTest.HandleInvalidElement
              WRITE_SimpleWritePort_ReadElementOpenRange: accessed-variable=SimpleWritePort.ReadElementOpenRange
              WRITE_SimpleWritePort_ReadElementRangeInfMax: accessed-variable=SimpleWritePort.ReadElementRangeInfMax
              WRITE_SimpleWritePort_SimpleReadElement: accessed-variable=SimpleWritePort.SimpleReadElement
              WRITE_SimpleWritePort_SimpleReadNeverReceived: accessed-variable=SimpleWritePort.SimpleReadNeverReceived
          14 x parameter access:
            PA_ArrayCalibration_arrayElement: accessed-parameter=ArrayCalibration.arrayElement
            PA_ArrayCalibration_variableArrayElem: accessed-parameter=ArrayCalibration.variableArrayElem
            PA_CalibrationPortInterface_CalibrationElement: accessed-parameter=CalibrationPortInterface.CalibrationElement
            PA_CalibrationPrimitiveType_notAccessibleElement: accessed-parameter=CalibrationPrimitiveType.notAccessibleElement
            PA_CalibrationPrimitiveType_readOnlyElement: accessed-parameter=CalibrationPrimitiveType.readOnlyElement
            PA_CalibrationPrimitiveType_readWriteElement: accessed-parameter=CalibrationPrimitiveType.readWriteElement
            PA_DoubleCalibration_doubleElem: accessed-parameter=DoubleCalibration.doubleElem
            PA_MultiArrayCalibration_multiArrayElement: accessed-parameter=MultiArrayCalibration.multiArrayElement
            PA_PerInstanceInternalCalibrationParameter: accessed-parameter=PerInstanceInternalCalibrationParameter
            PA_RefTypeCalibration_notAccessibleElement: accessed-parameter=RefTypeCalibration.notAccessibleElement
            PA_RefTypeCalibration_readOnlyElement: accessed-parameter=RefTypeCalibration.readOnlyElement
            PA_RefTypeCalibration_readWriteElement: accessed-parameter=RefTypeCalibration.readWriteElement
            PA_SharedInternalCalibrationParameter: accessed-parameter=SharedInternalCalibrationParameter
            PA_StructCalibration_Element: accessed-parameter=StructCalibration.Element
        ImplicitReadRunnable
          data-read-access:
            4 x access:
              REC_SimpleReadProto_ReadElementOpenRange: accessed-variable=SimpleReadProto.ReadElementOpenRange
              REC_SimpleReadProto_ReadElementRangeInfMax: accessed-variable=SimpleReadProto.ReadElementRangeInfMax
              REC_SimpleReadProto_SimpleReadElement: accessed-variable=SimpleReadProto.SimpleReadElement
              REC_SimpleReadTimeout_SimpleReadNeverReceived: accessed-variable=SimpleReadTimeout.SimpleReadNeverReceived
          14 x parameter access:
            PA_ArrayCalibration_arrayElement: accessed-parameter=ArrayCalibration.arrayElement
            PA_ArrayCalibration_variableArrayElem: accessed-parameter=ArrayCalibration.variableArrayElem
            PA_CalibrationPortInterface_CalibrationElement: accessed-parameter=CalibrationPortInterface.CalibrationElement
            PA_CalibrationPrimitiveType_notAccessibleElement: accessed-parameter=CalibrationPrimitiveType.notAccessibleElement
            PA_CalibrationPrimitiveType_readOnlyElement: accessed-parameter=CalibrationPrimitiveType.readOnlyElement
            PA_CalibrationPrimitiveType_readWriteElement: accessed-parameter=CalibrationPrimitiveType.readWriteElement
            PA_DoubleCalibration_doubleElem: accessed-parameter=DoubleCalibration.doubleElem
            PA_MultiArrayCalibration_multiArrayElement: accessed-parameter=MultiArrayCalibration.multiArrayElement
            PA_PerInstanceInternalCalibrationParameter: accessed-parameter=PerInstanceInternalCalibrationParameter
            PA_RefTypeCalibration_notAccessibleElement: accessed-parameter=RefTypeCalibration.notAccessibleElement
            PA_RefTypeCalibration_readOnlyElement: accessed-parameter=RefTypeCalibration.readOnlyElement
            PA_RefTypeCalibration_readWriteElement: accessed-parameter=RefTypeCalibration.readWriteElement
            PA_SharedInternalCalibrationParameter: accessed-parameter=SharedInternalCalibrationParameter
            PA_StructCalibration_Element: accessed-parameter=StructCalibration.Element
        InterVariableRunnable
          14 x parameter access:
            PA_ArrayCalibration_arrayElement: accessed-parameter=ArrayCalibration.arrayElement
            PA_ArrayCalibration_variableArrayElem: accessed-parameter=ArrayCalibration.variableArrayElem
            PA_CalibrationPortInterface_CalibrationElement: accessed-parameter=CalibrationPortInterface.CalibrationElement
            PA_CalibrationPrimitiveType_notAccessibleElement: accessed-parameter=CalibrationPrimitiveType.notAccessibleElement
            PA_CalibrationPrimitiveType_readOnlyElement: accessed-parameter=CalibrationPrimitiveType.readOnlyElement
            PA_CalibrationPrimitiveType_readWriteElement: accessed-parameter=CalibrationPrimitiveType.readWriteElement
            PA_DoubleCalibration_doubleElem: accessed-parameter=DoubleCalibration.doubleElem
            PA_MultiArrayCalibration_multiArrayElement: accessed-parameter=MultiArrayCalibration.multiArrayElement
            PA_PerInstanceInternalCalibrationParameter: accessed-parameter=PerInstanceInternalCalibrationParameter
            PA_RefTypeCalibration_notAccessibleElement: accessed-parameter=RefTypeCalibration.notAccessibleElement
            PA_RefTypeCalibration_readOnlyElement: accessed-parameter=RefTypeCalibration.readOnlyElement
            PA_RefTypeCalibration_readWriteElement: accessed-parameter=RefTypeCalibration.readWriteElement
            PA_SharedInternalCalibrationParameter: accessed-parameter=SharedInternalCalibrationParameter
            PA_StructCalibration_Element: accessed-parameter=StructCalibration.Element
          read-local-variables:
            4 x access:
              Read_ExplicitInterRunnableValue: accessed-variable=ExplicitInterRunnableValue
              Read_ExplicitInterRunnableValue_1: accessed-variable=ImplicitInterRunnableValue
              Read_ExplicitInterRunnableValue_1_1: accessed-variable=ExplicitInterRunnableStruct
              Read_ExplicitInterRunnableValue_1_1_1: accessed-variable=ImplicitInterRunnableStruct
          written-local-variables:
            4 x access:
              WRITE_ExplicitInterRunnableValue: accessed-variable=ExplicitInterRunnableValue
              WRITE_ExplicitInterRunnableValue_1: accessed-variable=ImplicitInterRunnableValue
              WRITE_ExplicitInterRunnableValue_1_1: accessed-variable=ExplicitInterRunnableStruct
              WRITE_ExplicitInterRunnableValue_1_1_1: accessed-variable=ImplicitInterRunnableStruct
        IsUpdatedRunnable
          data-receive-point-by-arguments:
            access REC_IsUpdatedByValuePrototype_IsUpdatedByArgumentElement: accessed-variable=IsUpdatedByValuePrototype.IsUpdatedByArgumentElement
          data-receive-point-by-values:
            access REC_IsUpdatedByValuePrototype_IdUpdatedByValueElement: accessed-variable=IsUpdatedByValuePrototype.IdUpdatedByValueElement
          14 x parameter access:
            PA_ArrayCalibration_arrayElement: accessed-parameter=ArrayCalibration.arrayElement
            PA_ArrayCalibration_variableArrayElem: accessed-parameter=ArrayCalibration.variableArrayElem
            PA_CalibrationPortInterface_CalibrationElement: accessed-parameter=CalibrationPortInterface.CalibrationElement
            PA_CalibrationPrimitiveType_notAccessibleElement: accessed-parameter=CalibrationPrimitiveType.notAccessibleElement
            PA_CalibrationPrimitiveType_readOnlyElement: accessed-parameter=CalibrationPrimitiveType.readOnlyElement
            PA_CalibrationPrimitiveType_readWriteElement: accessed-parameter=CalibrationPrimitiveType.readWriteElement
            PA_DoubleCalibration_doubleElem: accessed-parameter=DoubleCalibration.doubleElem
            PA_MultiArrayCalibration_multiArrayElement: accessed-parameter=MultiArrayCalibration.multiArrayElement
            PA_PerInstanceInternalCalibrationParameter: accessed-parameter=PerInstanceInternalCalibrationParameter
            PA_RefTypeCalibration_notAccessibleElement: accessed-parameter=RefTypeCalibration.notAccessibleElement
            PA_RefTypeCalibration_readOnlyElement: accessed-parameter=RefTypeCalibration.readOnlyElement
            PA_RefTypeCalibration_readWriteElement: accessed-parameter=RefTypeCalibration.readWriteElement
            PA_SharedInternalCalibrationParameter: accessed-parameter=SharedInternalCalibrationParameter
            PA_StructCalibration_Element: accessed-parameter=StructCalibration.Element
        ModeRunnable: mode-access-points=[EnhancedPortInterface.Mode, Mode_Port_Interface.ModeGroup]
          14 x parameter access:
            PA_ArrayCalibration_arrayElement: accessed-parameter=ArrayCalibration.arrayElement
            PA_ArrayCalibration_variableArrayElem: accessed-parameter=ArrayCalibration.variableArrayElem
            PA_CalibrationPortInterface_CalibrationElement: accessed-parameter=CalibrationPortInterface.CalibrationElement
            PA_CalibrationPrimitiveType_notAccessibleElement: accessed-parameter=CalibrationPrimitiveType.notAccessibleElement
            PA_CalibrationPrimitiveType_readOnlyElement: accessed-parameter=CalibrationPrimitiveType.readOnlyElement
            PA_CalibrationPrimitiveType_readWriteElement: accessed-parameter=CalibrationPrimitiveType.readWriteElement
            PA_DoubleCalibration_doubleElem: accessed-parameter=DoubleCalibration.doubleElem
            PA_MultiArrayCalibration_multiArrayElement: accessed-parameter=MultiArrayCalibration.multiArrayElement
            PA_PerInstanceInternalCalibrationParameter: accessed-parameter=PerInstanceInternalCalibrationParameter
            PA_RefTypeCalibration_notAccessibleElement: accessed-parameter=RefTypeCalibration.notAccessibleElement
            PA_RefTypeCalibration_readOnlyElement: accessed-parameter=RefTypeCalibration.readOnlyElement
            PA_RefTypeCalibration_readWriteElement: accessed-parameter=RefTypeCalibration.readWriteElement
            PA_SharedInternalCalibrationParameter: accessed-parameter=SharedInternalCalibrationParameter
            PA_StructCalibration_Element: accessed-parameter=StructCalibration.Element
        MultipleInstanciationRunnable
          data-receive-point-by-arguments:
            access REC_SimpleReadProto_SimpleReadElement: accessed-variable=SimpleReadProto.SimpleReadElement
          14 x parameter access:
            PA_ArrayCalibration_arrayElement: accessed-parameter=ArrayCalibration.arrayElement
            PA_ArrayCalibration_variableArrayElem: accessed-parameter=ArrayCalibration.variableArrayElem
            PA_CalibrationPortInterface_CalibrationElement: accessed-parameter=CalibrationPortInterface.CalibrationElement
            PA_CalibrationPrimitiveType_notAccessibleElement: accessed-parameter=CalibrationPrimitiveType.notAccessibleElement
            PA_CalibrationPrimitiveType_readOnlyElement: accessed-parameter=CalibrationPrimitiveType.readOnlyElement
            PA_CalibrationPrimitiveType_readWriteElement: accessed-parameter=CalibrationPrimitiveType.readWriteElement
            PA_DoubleCalibration_doubleElem: accessed-parameter=DoubleCalibration.doubleElem
            PA_MultiArrayCalibration_multiArrayElement: accessed-parameter=MultiArrayCalibration.multiArrayElement
            PA_PerInstanceInternalCalibrationParameter: accessed-parameter=PerInstanceInternalCalibrationParameter
            PA_RefTypeCalibration_notAccessibleElement: accessed-parameter=RefTypeCalibration.notAccessibleElement
            PA_RefTypeCalibration_readOnlyElement: accessed-parameter=RefTypeCalibration.readOnlyElement
            PA_RefTypeCalibration_readWriteElement: accessed-parameter=RefTypeCalibration.readWriteElement
            PA_SharedInternalCalibrationParameter: accessed-parameter=SharedInternalCalibrationParameter
            PA_StructCalibration_Element: accessed-parameter=StructCalibration.Element
        ReceiveRecordRunnable
          14 x parameter access:
            PA_ArrayCalibration_arrayElement: accessed-parameter=ArrayCalibration.arrayElement
            PA_ArrayCalibration_variableArrayElem: accessed-parameter=ArrayCalibration.variableArrayElem
            PA_CalibrationPortInterface_CalibrationElement: accessed-parameter=CalibrationPortInterface.CalibrationElement
            PA_CalibrationPrimitiveType_notAccessibleElement: accessed-parameter=CalibrationPrimitiveType.notAccessibleElement
            PA_CalibrationPrimitiveType_readOnlyElement: accessed-parameter=CalibrationPrimitiveType.readOnlyElement
            PA_CalibrationPrimitiveType_readWriteElement: accessed-parameter=CalibrationPrimitiveType.readWriteElement
            PA_DoubleCalibration_doubleElem: accessed-parameter=DoubleCalibration.doubleElem
            PA_MultiArrayCalibration_multiArrayElement: accessed-parameter=MultiArrayCalibration.multiArrayElement
            PA_PerInstanceInternalCalibrationParameter: accessed-parameter=PerInstanceInternalCalibrationParameter
            PA_RefTypeCalibration_notAccessibleElement: accessed-parameter=RefTypeCalibration.notAccessibleElement
            PA_RefTypeCalibration_readOnlyElement: accessed-parameter=RefTypeCalibration.readOnlyElement
            PA_RefTypeCalibration_readWriteElement: accessed-parameter=RefTypeCalibration.readWriteElement
            PA_SharedInternalCalibrationParameter: accessed-parameter=SharedInternalCalibrationParameter
            PA_StructCalibration_Element: accessed-parameter=StructCalibration.Element
        ServiceRunnable
          6 x asynchronous server call result point:
            ASCRP_NvSWC_NvMService_client_GetErrorStatus: asynchronous-server-call-point=AC_NvSWC_NvMService_client_GetErrorStatus
            ASCRP_ServerCallRunnable_SC_NvMService_GetErrorStatus: asynchronous-server-call-point=SC_NvMService_GetErrorStatus
            ASCRP_ServerCallRunnable_SC_NvSWC_NvMAdministration_client_SetBlockProtection: asynchronous-server-call-point=SC_NvSWC_NvMAdministration_client_SetBlockProtection
            ASCRP_ServiceRunnable_AC_NvSWC_NvMService_AC2_SRBS_Defs_client_SetRamBlockStatus: asynchronous-server-call-point=AC_NvSWC_NvMService_AC2_SRBS_Defs_client_SetRamBlockStatus
            ASCRP_ServiceRunnable_AC_NvSWC_NvMService_AC2_SRBS_Defs_client_WriteBlock: asynchronous-server-call-point=AC_NvSWC_NvMService_AC2_SRBS_Defs_client_WriteBlock
            ASCRP_ServiceRunnable_SC_CallPortInterface_OtherIntOperation: asynchronous-server-call-point=SC_CallPortInterface_OtherIntOperation
          14 x parameter access:
            PA_ArrayCalibration_arrayElement: accessed-parameter=ArrayCalibration.arrayElement
            PA_ArrayCalibration_variableArrayElem: accessed-parameter=ArrayCalibration.variableArrayElem
            PA_CalibrationPortInterface_CalibrationElement: accessed-parameter=CalibrationPortInterface.CalibrationElement
            PA_CalibrationPrimitiveType_notAccessibleElement: accessed-parameter=CalibrationPrimitiveType.notAccessibleElement
            PA_CalibrationPrimitiveType_readOnlyElement: accessed-parameter=CalibrationPrimitiveType.readOnlyElement
            PA_CalibrationPrimitiveType_readWriteElement: accessed-parameter=CalibrationPrimitiveType.readWriteElement
            PA_DoubleCalibration_doubleElem: accessed-parameter=DoubleCalibration.doubleElem
            PA_MultiArrayCalibration_multiArrayElement: accessed-parameter=MultiArrayCalibration.multiArrayElement
            PA_PerInstanceInternalCalibrationParameter: accessed-parameter=PerInstanceInternalCalibrationParameter
            PA_RefTypeCalibration_notAccessibleElement: accessed-parameter=RefTypeCalibration.notAccessibleElement
            PA_RefTypeCalibration_readOnlyElement: accessed-parameter=RefTypeCalibration.readOnlyElement
            PA_RefTypeCalibration_readWriteElement: accessed-parameter=RefTypeCalibration.readWriteElement
            PA_SharedInternalCalibrationParameter: accessed-parameter=SharedInternalCalibrationParameter
            PA_StructCalibration_Element: accessed-parameter=StructCalibration.Element
          5 x async call:
            AC_NvSWC_NvMService_AC2_SRBS_Defs_client_SetRamBlockStatus: operation=NvSWC_NvMService_AC2_SRBS_Defs_client.SetRamBlockStatus, timeout=2
            AC_NvSWC_NvMService_AC2_SRBS_Defs_client_WriteBlock: operation=NvSWC_NvMService_AC2_SRBS_Defs_client.WriteBlock, timeout=0
            SC_CallPortInterface_OtherIntOperation: operation=CallPortInterface.InOutOperation, timeout=0
            SC_NvMService_GetErrorStatus: operation=NvMService_service_client.GetErrorStatus, timeout=2
            SC_NvSWC_NvMAdministration_client_SetBlockProtection: operation=NvSWC_NvMAdministration_client.SetBlockProtection, timeout=2
          7 x sync call:
            SC_CallPortInterface_SimpleIntOperation: operation=CallPortInterface.SimpleIntOperation, timeout=0.01
            SC_NvSWC_NvMNotifyInitBlock_client_InitBlock: operation=NvSWC_NvMNotifyInitBlock_client.InitBlock, timeout=0
            SC_NvSWC_NvMService_AC2_client_GetErrorStatus: operation=NvSWC_NvMService_AC2_client.GetErrorStatus, timeout=0
            SC_NvSWC_NvMService_AC2_client_ReadBlock: operation=NvSWC_NvMService_AC2_client.ReadBlock, timeout=0
            SC_NvSWC_NvMService_AC2_client_WriteBlock: operation=NvSWC_NvMService_AC2_client.WriteBlock, timeout=0
            SC_NvSWC_NvMService_AC2_SRBS_Defs_client_GetErrorStatus: operation=NvSWC_NvMService_AC2_SRBS_Defs_client.GetErrorStatus, timeout=1E-05
            SC_NvSWC_NvMService_AC2_SRBS_Defs_client_RestoreBlockDefaults: operation=NvSWC_NvMService_AC2_SRBS_Defs_client.RestoreBlockDefaults, timeout=0
          4 x wait point:
            WP_NvSWC_NvMService_client_GetErrorStatus: timeout=3, trigger=ASCRE_NvSWC_NvMService_client_GetErrorStatus
            WP_ServerCallRunnable_SC_NvSWC_NvMAdministration_client_SetBlockProtection: timeout=2, trigger=ASCRE_ServerCallRunnable_SC_NvSWC_NvMAdministration_client_SetBlockProtection
            WP_ServiceRunnable_AC_NvSWC_NvMService_AC2_SRBS_Defs_client_SetRamBlockStatus: timeout=2, trigger=ASCRE_ServiceRunnable_AC_NvSWC_NvMService_AC2_SRBS_Defs_client_SetRamBlockStatus
            WP_ServiceRunnable_SC_CallPortInterface_OtherIntOperation: trigger=ASCRE_ServiceRunnable_SC_CallPortInterface_OtherIntOperation
        StructRunnable
          data-read-access:
            access READ_StructSRInterface_IElement: accessed-variable=StructSRInterface.IElement
          data-receive-point-by-arguments:
            access REC_StructSRInterface_Element: accessed-variable=StructSRInterface.Element
          data-send-points:
            access SEND_StructSRInterface_Element: accessed-variable=StructSRInterface.Element
          data-write-access:
            access WRITE_StructSRInterface_IElement: accessed-variable=StructSRInterface.IElement
          14 x parameter access:
            PA_ArrayCalibration_arrayElement: accessed-parameter=ArrayCalibration.arrayElement
            PA_ArrayCalibration_variableArrayElem: accessed-parameter=ArrayCalibration.variableArrayElem
            PA_CalibrationPortInterface_CalibrationElement: accessed-parameter=CalibrationPortInterface.CalibrationElement
            PA_CalibrationPrimitiveType_notAccessibleElement: accessed-parameter=CalibrationPrimitiveType.notAccessibleElement
            PA_CalibrationPrimitiveType_readOnlyElement: accessed-parameter=CalibrationPrimitiveType.readOnlyElement
            PA_CalibrationPrimitiveType_readWriteElement: accessed-parameter=CalibrationPrimitiveType.readWriteElement
            PA_DoubleCalibration_doubleElem: accessed-parameter=DoubleCalibration.doubleElem
            PA_MultiArrayCalibration_multiArrayElement: accessed-parameter=MultiArrayCalibration.multiArrayElement
            PA_PerInstanceInternalCalibrationParameter: accessed-parameter=PerInstanceInternalCalibrationParameter
            PA_RefTypeCalibration_notAccessibleElement: accessed-parameter=RefTypeCalibration.notAccessibleElement
            PA_RefTypeCalibration_readOnlyElement: accessed-parameter=RefTypeCalibration.readOnlyElement
            PA_RefTypeCalibration_readWriteElement: accessed-parameter=RefTypeCalibration.readWriteElement
            PA_SharedInternalCalibrationParameter: accessed-parameter=SharedInternalCalibrationParameter
            PA_StructCalibration_Element: accessed-parameter=StructCalibration.Element
          sync call SC_StructCSInterface_cloneStruct: operation=StructCSInterface.cloneStruct, timeout=0
        TriggerRunnable: external-triggering-points=[TriggerInterface.SomeTriggerElement, TriggerInterfaceError.SomeTriggerElement]
          14 x parameter access:
            PA_ArrayCalibration_arrayElement: accessed-parameter=ArrayCalibration.arrayElement
            PA_ArrayCalibration_variableArrayElem: accessed-parameter=ArrayCalibration.variableArrayElem
            PA_CalibrationPortInterface_CalibrationElement: accessed-parameter=CalibrationPortInterface.CalibrationElement
            PA_CalibrationPrimitiveType_notAccessibleElement: accessed-parameter=CalibrationPrimitiveType.notAccessibleElement
            PA_CalibrationPrimitiveType_readOnlyElement: accessed-parameter=CalibrationPrimitiveType.readOnlyElement
            PA_CalibrationPrimitiveType_readWriteElement: accessed-parameter=CalibrationPrimitiveType.readWriteElement
            PA_DoubleCalibration_doubleElem: accessed-parameter=DoubleCalibration.doubleElem
            PA_MultiArrayCalibration_multiArrayElement: accessed-parameter=MultiArrayCalibration.multiArrayElement
            PA_PerInstanceInternalCalibrationParameter: accessed-parameter=PerInstanceInternalCalibrationParameter
            PA_RefTypeCalibration_notAccessibleElement: accessed-parameter=RefTypeCalibration.notAccessibleElement
            PA_RefTypeCalibration_readOnlyElement: accessed-parameter=RefTypeCalibration.readOnlyElement
            PA_RefTypeCalibration_readWriteElement: accessed-parameter=RefTypeCalibration.readWriteElement
            PA_SharedInternalCalibrationParameter: accessed-parameter=SharedInternalCalibrationParameter
            PA_StructCalibration_Element: accessed-parameter=StructCalibration.Element
        UnionRunnable
          data-read-access:
            access REC_UnionSRInterface_implicitElem: accessed-variable=UnionSRInterface.implicitElem
          data-receive-point-by-arguments:
            access REC_UnionSRInterface_explicitElem: accessed-variable=UnionSRInterface.explicitElem
          data-send-points:
            access SEND_UnionSRInterface_explicitElem: accessed-variable=UnionSRInterface.explicitElem
          data-write-access:
            access SEND_UnionSRInterface_implicitElem: accessed-variable=UnionSRInterface.implicitElem
          14 x parameter access:
            PA_ArrayCalibration_arrayElement: accessed-parameter=ArrayCalibration.arrayElement
            PA_ArrayCalibration_variableArrayElem: accessed-parameter=ArrayCalibration.variableArrayElem
            PA_CalibrationPortInterface_CalibrationElement: accessed-parameter=CalibrationPortInterface.CalibrationElement
            PA_CalibrationPrimitiveType_notAccessibleElement: accessed-parameter=CalibrationPrimitiveType.notAccessibleElement
            PA_CalibrationPrimitiveType_readOnlyElement: accessed-parameter=CalibrationPrimitiveType.readOnlyElement
            PA_CalibrationPrimitiveType_readWriteElement: accessed-parameter=CalibrationPrimitiveType.readWriteElement
            PA_DoubleCalibration_doubleElem: accessed-parameter=DoubleCalibration.doubleElem
            PA_MultiArrayCalibration_multiArrayElement: accessed-parameter=MultiArrayCalibration.multiArrayElement
            PA_PerInstanceInternalCalibrationParameter: accessed-parameter=PerInstanceInternalCalibrationParameter
            PA_RefTypeCalibration_notAccessibleElement: accessed-parameter=RefTypeCalibration.notAccessibleElement
            PA_RefTypeCalibration_readOnlyElement: accessed-parameter=RefTypeCalibration.readOnlyElement
            PA_RefTypeCalibration_readWriteElement: accessed-parameter=RefTypeCalibration.readWriteElement
            PA_SharedInternalCalibrationParameter: accessed-parameter=SharedInternalCalibrationParameter
            PA_StructCalibration_Element: accessed-parameter=StructCalibration.Element
          sync call SC_UnionCInterface_f: operation=UnionCInterface.f, timeout=0
      swc service dependency NvBlockNeed: category=SERVICE, assigned-ports=role-based-port-assignment={port-prototype=NvMAdministration_service_server, role=NvMAdmin}
        service-needs:
          nv block needs NvBlockNeed: n-data-sets=0, ram-block-status-control=API, reliability=NO-PROTECTION, restore-at-start=false, store-at-shutdown=false
      shared-parameters:
        parameter data prototype SharedInternalCalibrationParameter: sw-calibration-access=READ-WRITE, type=Uint8Constr
  swc implementation AP_Hello_World_Implementation: behavior=AP_Hello_World_InternalBehavior
    code-descriptors:
      code Default: artifact-descriptors=autosar-engineering-object=category=SWSRC
package /ComponentTypes/DataTypeMappingSets
  data type mapping set CustomMap
    data-type-maps:
      application-data-type=Boolean, implementation-data-type=boolean
      application-data-type=Int16, implementation-data-type=sint16
      application-data-type=IntArray, implementation-data-type=IntArrayImpl
      application-data-type=multiArrayTwo, implementation-data-type=multiArrayTwoImpl
      application-data-type=multiArrayThree, implementation-data-type=multiArrayThreeImpl
      application-data-type=SimpleStruct, implementation-data-type=SimpleStructImpl
      application-data-type=ComplexStruct, implementation-data-type=ComplexStructImpl
      application-data-type=variableArray, implementation-data-type=variableArrayImpl
      application-data-type=Uint8Constr, implementation-data-type=customUInt8
      application-data-type=Uint8ImplConstr, implementation-data-type=UintConstrImpl
      application-data-type=Uint8AllConstr, implementation-data-type=UintConstrImpl
      application-data-type=Uint8, implementation-data-type=uint8
      application-data-type=doubleConstrInfOpen, implementation-data-type=customFloat64
  data type mapping set RecordMapping
    data-type-maps:
      application-data-type=SomeFloatValue, implementation-data-type=float32
      application-data-type=CustomSignedValue, implementation-data-type=sint16
      application-data-type=FloatArray, implementation-data-type=FloatArrayImplementation
      application-data-type=CustomStringType, implementation-data-type=CharArrayImplementation
      application-data-type=CustomVariableStringType, implementation-data-type=VariableStringImplementation
      application-data-type=SignedValue, implementation-data-type=sint16
      application-data-type=CustomFloat_RangeInfMax, implementation-data-type=customDouble32
      application-data-type=CustomSignedValue_RangeOpen, implementation-data-type=sint8
package /DataTypes
  5 x application array data type, all with category=ARRAY, sw-calibration-access=READ-ONLY:
    FloatArray
      element SomeFloatValues: category=VALUE, type=SomeFloatValue, array-size-semantics=FIXED-SIZE, max-number-of-elements=15
    IntArray
      element intElement: category=VALUE, type=Int16, array-size-semantics=FIXED-SIZE, max-number-of-elements=10
    multiArrayThree
      element elementTwo: category=ARRAY, type=multiArrayTwo, array-size-semantics=FIXED-SIZE, max-number-of-elements=2
    multiArrayTwo
      element arrayElement: category=ARRAY, type=IntArray, array-size-semantics=FIXED-SIZE, max-number-of-elements=3
    variableArray
      element intElement: category=VALUE, type=Uint8, array-size-semantics=VARIABLE-SIZE, max-number-of-elements=10
  16 x app type, all with sw-calibration-access=READ-ONLY:
    Boolean: category=BOOLEAN, compu {else 0}
    CustomFloat_RangeInfMax: category=VALUE, range raw -INF..<100
    CustomSignedValue: category=BOOLEAN, range raw -42..123, invalid-value=42
    CustomSignedValue_RangeOpen: category=BOOLEAN, range raw >0..<100, invalid-value=42
    CustomStringType: category=STRING, sw-text-props={array-size-semantics=FIXED-SIZE, sw-max-text-size=30, sw-fill-character=67}
    CustomVariableStringType: category=STRING, sw-text-props={array-size-semantics=VARIABLE-SIZE, sw-max-text-size=70, sw-fill-character=70}
    doubleConstrInfOpen: category=VALUE, range raw 20000..40000
    FloatButImplConstrained: category=VALUE
    Int16: category=VALUE
    Int16Constr: category=VALUE, range raw 1..10
    SignedValue: category=VALUE
    SomeFloatValue: category=VALUE, unit=SomeFloatingUnit
    Uint8: category=VALUE
    Uint8AllConstr: category=VALUE, range raw 1..10
    Uint8Constr: category=VALUE, range raw 1..10
    Uint8ImplConstr: category=VALUE
  application record data type ComplexStruct: category=STRUCTURE, sw-calibration-access=READ-ONLY
    4 x application record element:
      intElement: category=VALUE, type=Int16Constr
      floatElement: category=VALUE, type=FloatButImplConstrained
      arrayElement: category=ARRAY, type=IntArray
      structElement: category=STRUCTURE, type=SimpleStruct
  application record data type SimpleStruct: category=STRUCTURE, sw-calibration-access=READ-ONLY
    application record element boolElement: category=BOOLEAN, type=Boolean
    application record element constrElement: category=BOOLEAN, type=CustomSignedValue_RangeOpen
  16 x impl type, all with sw-calibration-access=READ-ONLY, type-emitter=RTE:
    ArrayOfTypeReferences: category=ARRAY
      element TypeReferenceSubElement: array-size=14, array-size-semantics=FIXED-SIZE, implementation-data-type=doubleImpl
    CharArrayImplementation: category=ARRAY
      element Char: category=VALUE, array-size=30, array-size-semantics=FIXED-SIZE, base-type=CustomCharBaseType, sw-calibration-access=READ-ONLY
    ComplexStructImpl: category=STRUCTURE
      4 x element:
        intElement: category=VALUE, base-type=CustomSint16, sw-calibration-access=READ-ONLY
        floatElement: category=VALUE, base-type=CustomFloatBaseType, sw-calibration-access=READ-ONLY, range raw -INF..<100
        arrrayElement: implementation-data-type=IntArrayImpl
        structElement: implementation-data-type=SimpleStructImpl
    customDouble32: category=VALUE, base-type=customDouble32
    customFloat64: category=VALUE, base-type=customFloat64
    customUInt8: category=VALUE, base-type=customUInt8
    doubleImpl: category=VALUE, base-type=customFloat64
    FloatArrayImplementation: category=ARRAY
      element CustomFloatElement: category=VALUE, array-size=15, array-size-semantics=FIXED-SIZE, base-type=CustomFloatBaseType, sw-calibration-access=READ-ONLY
    IntArrayImpl: category=ARRAY
      element intElement: category=VALUE, array-size=10, array-size-semantics=FIXED-SIZE, base-type=CustomSint16, sw-calibration-access=READ-ONLY
    multiArrayThreeImpl: category=ARRAY
      element Element: array-size=2, array-size-semantics=FIXED-SIZE, sw-calibration-access=READ-ONLY, implementation-data-type=multiArrayTwoImpl
    multiArrayTwoImpl: category=ARRAY
      element arrayElement: array-size=3, array-size-semantics=FIXED-SIZE, implementation-data-type=IntArrayImpl
    SimpleStructImpl: category=STRUCTURE
      element boolElement: category=VALUE, base-type=customBoolean, sw-calibration-access=READ-ONLY
      element constrElement: implementation-data-type=sint8
    UintConstrImpl: category=VALUE, base-type=customUInt8, range raw 1..20
    unionImpl: category=UNION
      element valueElem: category=VALUE, base-type=customUInt8, sw-calibration-access=READ-ONLY, range raw >0..<100
      element arrayElem: category=ARRAY, sw-calibration-access=READ-ONLY
        element intElem: category=VALUE, array-size=5, array-size-semantics=FIXED-SIZE, base-type=customUInt8, sw-calibration-access=READ-ONLY, range raw 1..10
      element structElem: category=STRUCTURE, sw-calibration-access=READ-ONLY
        element intElem: category=VALUE, base-type=customUInt8, sw-calibration-access=READ-ONLY, range raw 1..10
    variableArrayImpl: category=ARRAY
      element Element: category=VALUE, array-size=10, array-size-semantics=VARIABLE-SIZE, base-type=customUInt8, sw-calibration-access=READ-ONLY
    VariableStringImplementation: category=STRUCTURE
      element SizeElement: category=VALUE, base-type=CustomSizeType, sw-calibration-access=READ-ONLY
      element DataElement: category=ARRAY, sw-calibration-access=READ-ONLY
        element Element: category=VALUE, array-size=70, array-size-handling=ALL-INDICES-SAME-ARRAY-SIZE, array-size-semantics=VARIABLE-SIZE, base-type=CustomCharBaseType, sw-calibration-access=READ-ONLY
package /DataTypes/BaseTypes
  8 x base type, all with category=FIXED_LENGTH:
    customBoolean: base-type-size=1, base-type-encoding=BOOLEAN, native-declaration=boolean
    CustomCharBaseType: base-type-size=8, base-type-encoding=NONE, native-declaration=uint8
    customDouble32: base-type-size=32, base-type-encoding=IEEE754, native-declaration=float32
    customFloat64: base-type-size=64, base-type-encoding=IEEE754, native-declaration=float64
    CustomFloatBaseType: base-type-size=32, base-type-encoding=IEEE754, native-declaration=float32
    CustomSint16: base-type-size=16, base-type-encoding=2C, native-declaration=sint16
    CustomSizeType: base-type-size=16, base-type-encoding=NONE, native-declaration=uint16
    customUInt8: base-type-size=8, base-type-encoding=NONE, native-declaration=uint8
package /DataTypes/Units
  unit SomeFloatingUnit: factor-si-to-unit=1, offset-si-to-unit=0
package /ModeDclrGroups
  mode declaration group ExplicitModeGroup: category=EXPLICIT_ORDER, initial-mode=Init, on-transition-value=4
    mode Init: value=0
    mode Last: value=2
    mode Next: value=1
  mode declaration group ModeDeclarationGroup: category=ALPHABETIC_ORDER, initial-mode=SomeMode, on-transition-value=32
    mode SomeMode: value=1
    mode SomeOtherMode: value=2
package /PortInterfaces
  6 x client server interface:
    ArrayCSPort
      operation Operation
      operation sumArray
        arg arg: type=IntArray, direction=IN, server-argument-impl-policy=USE-ARGUMENT-TYPE
        arg arg_1: type=IntArray, direction=INOUT, server-argument-impl-policy=USE-ARGUMENT-TYPE
        arg arg_2: type=IntArray, direction=OUT, server-argument-impl-policy=USE-ARGUMENT-TYPE
    CallPortInterface
      operation InOutOperation
        arg int_var: type=sint16, direction=INOUT, server-argument-impl-policy=USE-ARGUMENT-TYPE
        arg struct_var: type=ComplexStruct, direction=INOUT, server-argument-impl-policy=USE-ARGUMENT-TYPE
        arg array_var: type=FloatArray, direction=INOUT, server-argument-impl-policy=USE-ARGUMENT-TYPE
      operation SimpleIntOperation
        arg arg: type=sint16, direction=IN, server-argument-impl-policy=USE-ARGUMENT-TYPE
        arg arg_1: type=CustomFloat_RangeInfMax, direction=INOUT, server-argument-impl-policy=USE-ARGUMENT-TYPE
    DoubleCSPort
      operation f
        arg arg: type=doubleConstrInfOpen, direction=IN, server-argument-impl-policy=USE-ARGUMENT-TYPE
        arg arg_1: type=doubleConstrInfOpen, direction=OUT, server-argument-impl-policy=USE-ARGUMENT-TYPE
    StructCSPort
      operation cloneStruct
        arg arg: type=ComplexStruct, direction=IN, server-argument-impl-policy=USE-ARGUMENT-TYPE
        arg arg_1: type=ComplexStruct, direction=OUT, server-argument-impl-policy=USE-ARGUMENT-TYPE
      operation Operation
    UnionCSPort
      operation f
        arg arg: type=unionImpl, direction=INOUT, server-argument-impl-policy=USE-ARGUMENT-TYPE
    VariableArrayCSPort
      operation f
        arg arg: type=variableArray, direction=IN, server-argument-impl-policy=USE-ARGUMENT-TYPE
        arg arg_1: type=variableArray, direction=OUT, server-argument-impl-policy=USE-ARGUMENT-TYPE
  mode switch interface ExplicitModePort
    mode group Mode: type=ExplicitModeGroup
  mode switch interface Mode_Port_Interface
    mode group ModeGroup: type=ModeDeclarationGroup
  nv data interface SimpleNvDataInterface
    nv-datas:
      data element_OneToTen: range raw 1..10, type=uint64
  7 x parameter interface:
    ArrayCalibration
      parameter data prototype arrayElement: sw-calibration-access=READ-WRITE, type=IntArrayImpl
      parameter data prototype variableArrayElem: sw-calibration-access=READ-WRITE, range raw 1..10, type=variableArray
    CalibrationPortInterface
      parameter data prototype CalibrationElement: sw-calibration-access=READ-WRITE, type=uint16
    CalibrationPrimitiveType
      parameter data prototype notAccessibleElement: range raw 1..10, type=uint8
      parameter data prototype readOnlyElement: sw-calibration-access=READ-ONLY, type=uint8
      parameter data prototype readWriteElement: sw-calibration-access=READ-WRITE, type=uint8
    CalibrationRefType
      parameter data prototype notAccessibleElement: type=CustomStringType
      parameter data prototype readOnlyElement: sw-calibration-access=READ-ONLY, type=CustomStringType
      parameter data prototype readWriteElement: sw-calibration-access=READ-WRITE, type=CustomStringType
    DoubleCalibrationPort
      parameter data prototype doubleElem: sw-calibration-access=READ-WRITE, type=doubleConstrInfOpen
    MultiArrayCalibration
      parameter data prototype multiArrayElement: sw-calibration-access=READ-WRITE, type=multiArrayThree
    StructCalibration
      parameter data prototype Element: sw-calibration-access=READ-WRITE, type=ComplexStruct
  13 x sender receiver interface:
    AcknowledgmentPort
      data nonWaitElement: type=uint64
      data waitElement: type=uint64
      invalidation-policys:
        data-element=waitElement, handle-invalid=DONT-INVALIDATE
        data-element=nonWaitElement, handle-invalid=DONT-INVALIDATE
    ArraySRPort
      8 x data, all with type=IntArray:
        acknowlegdement
        constraint: range raw 1..10
        errorHandling
        handleKeep
        Iconstraint: range raw 1..10
        init
        initConstraint: range raw 1..10
        INone
      invalidation-policys:
        handle-invalid=REPLACE
        handle-invalid=REPLACE
        data-element=acknowlegdement, handle-invalid=KEEP
        handle-invalid=KEEP
        handle-invalid=KEEP
        handle-invalid=REPLACE
        data-element=handleKeep, handle-invalid=KEEP
        data-element=constraint, handle-invalid=REPLACE
        data-element=errorHandling, handle-invalid=KEEP
        handle-invalid=KEEP
        data-element=Iconstraint, handle-invalid=KEEP
        handle-invalid=KEEP
        data-element=init, handle-invalid=KEEP
        data-element=initConstraint, handle-invalid=KEEP
        data-element=INone, handle-invalid=DONT-INVALIDATE
    BooleanSRPort: invalidation-policy{data-element=isElement, handle-invalid=DONT-INVALIDATE}
      data isElement: type=Boolean
    ComplexPortTest
      5 x data:
        ArrayOfTypeRefElement: type=ArrayOfTypeReferences
        ComplexElement: type=NvM_RequestResultType
        ConstrainedElement: range raw 0..18446744073709551615, type=uint64
        HandleInvalidElement: type=uint64
        QueuedElement: range raw 0..4294967295, sw-impl-policy=QUEUED, type=uint64  # uint64 with uint32_DataConstr data constraint.
      invalidation-policys:
        data-element=HandleInvalidElement, handle-invalid=REPLACE
        data-element=ComplexElement, handle-invalid=DONT-INVALIDATE
        data-element=ConstrainedElement, handle-invalid=DONT-INVALIDATE
        data-element=QueuedElement, handle-invalid=DONT-INVALIDATE
        data-element=ArrayOfTypeRefElement, handle-invalid=DONT-INVALIDATE
    DataConstraintPort
      10 x data:
        AllConstr: range raw >0..<100, type=Uint8AllConstr
        ApplicationTypeAllConstr: type=Uint8AllConstr
        ApplicationTypeConstr: type=Uint8Constr
        ApplicationTypeImplConstr: type=Uint8ImplConstr
        DataProtypeApplConstr: range raw >0..<100, type=Uint8Constr
        DataProtypeConstr: range raw >0..<100, type=Uint8
        DataProtypeImplConstr: range raw >0..<100, type=Uint8ImplConstr
        ImplementationTypeConstr: type=UintConstrImpl
        InfFloatConstr: range raw -INF..INF, type=float32
        NoConstr: type=Uint8
      invalidation-policys:
        data-element=DataProtypeConstr, handle-invalid=DONT-INVALIDATE
        data-element=DataProtypeApplConstr, handle-invalid=DONT-INVALIDATE
        data-element=DataProtypeImplConstr, handle-invalid=DONT-INVALIDATE
        data-element=NoConstr, handle-invalid=DONT-INVALIDATE
        data-element=AllConstr, handle-invalid=DONT-INVALIDATE
        data-element=ApplicationTypeConstr, handle-invalid=DONT-INVALIDATE
        data-element=ApplicationTypeImplConstr, handle-invalid=DONT-INVALIDATE
        data-element=ApplicationTypeAllConstr, handle-invalid=DONT-INVALIDATE
        data-element=ImplementationTypeConstr, handle-invalid=DONT-INVALIDATE
        data-element=InfFloatConstr, handle-invalid=DONT-INVALIDATE
    DoubleSRPort
      data explicitElem: type=doubleConstrInfOpen
      data implicitElem: type=doubleConstrInfOpen
      invalidation-policys:
        data-element=DoubleSRPort/implicitElem, handle-invalid=DONT-INVALIDATE
        data-element=DoubleSRPort/explicitElem, handle-invalid=DONT-INVALIDATE
    Hello_World_port_interface: invalidation-policy{data-element=Hello_World_Element, handle-invalid=REPLACE}
      data Hello_World_Element: type=boolean
    IsUpdatedByValuePortInterface
      data IdUpdatedByValueElement: type=uint64
      data IsUpdatedByArgumentElement: type=uint64
      invalidation-policys:
        data-element=IdUpdatedByValueElement, handle-invalid=DONT-INVALIDATE
        data-element=IsUpdatedByArgumentElement, handle-invalid=DONT-INVALIDATE
    MultiArraySRPort
      data multiArray: type=multiArrayThree
      data multiArrayConstraint: range raw 1..10, type=multiArrayThree
      data multiArrayConstraintImplicit: range raw 1..10, type=multiArrayThree
      invalidation-policys:
        data-element=multiArrayConstraintImplicit, handle-invalid=KEEP
        data-element=multiArray, handle-invalid=DONT-INVALIDATE
        data-element=multiArrayConstraint, handle-invalid=DONT-INVALIDATE
    SimpleReadInterface
      4 x data:
        ReadElementOpenRange: range raw >0..<100, type=CustomSignedValue_RangeOpen
        ReadElementRangeInfMax: type=CustomFloat_RangeInfMax
        SimpleReadElement: range raw -42..123, type=CustomSignedValue
        SimpleReadNeverReceived: type=uint64
      invalidation-policys:
        data-element=ReadElementOpenRange, handle-invalid=KEEP
        data-element=SimpleReadElement, handle-invalid=DONT-INVALIDATE
        data-element=ReadElementRangeInfMax, handle-invalid=DONT-INVALIDATE
        data-element=SimpleReadNeverReceived, handle-invalid=DONT-INVALIDATE
    StructSRPort
      data Element: type=ComplexStruct
      data IElement: type=ComplexStruct
      invalidation-policys:
        data-element=Element, handle-invalid=DONT-INVALIDATE
        data-element=IElement, handle-invalid=DONT-INVALIDATE
    UnionSRPort
      data explicitElem: type=unionImpl
      data implicitElem: type=unionImpl
      invalidation-policys:
        data-element=UnionSRPort/explicitElem, handle-invalid=DONT-INVALIDATE
        data-element=UnionSRPort/implicitElem, handle-invalid=DONT-INVALIDATE
    VariableArraySR: invalidation-policy{data-element=variableArrayConstr, handle-invalid=DONT-INVALIDATE}
      data variableArrayConstr: range raw 1..10, sw-impl-policy=QUEUED, type=variableArray
  trigger interface SomeTriggerInterface
    trigger SomeTriggerElement
package /Predefined_DEV/ImplementationDataTypes
  impl type Dem_UdsStatusByteType: compu {mask 1: 1=DEM_UDS_STATUS_TF, mask 2: 2=DEM_UDS_STATUS_TFTOC, mask 4: 4=DEM_UDS_STATUS_PDTC, mask 8: 8=DEM_UDS_STATUS_CDTC, mask 16: 16=DEM_UDS_STATUS_TNCSLC, mask 32: 32=DEM_UDS_STATUS_TFSLC, mask 64: 64=DEM_UDS_STATUS_TNCTOC, mask 128: 128=DEM_UDS_STATUS_WIR}, range raw 0..255, implementation-data-type=uint8
  impl type NvM_RequestResultType: compu {0=NVM_REQ_OK, 1=NVM_REQ_NOT_OK, 2=NVM_REQ_PENDING, 3=NVM_REQ_INTEGRITY_FAILED, 4=NVM_REQ_BLOCK_SKIPPED, 5=NVM_REQ_NV_INVALIDATED, 6=NVM_REQ_CANCELED, 7=NVM_REQ_REDUNDANCY_FAILED, 8=NVM_REQ_RESTORED_FROM_ROM}, implementation-data-type=uint8
package /Predefined_DEV/PortInterfaces
  8 x client server interface:
    CallbackDTCStatusChange: is-service=true, service-kind=DIAGNOSTIC-EVENT-MANAGER
      operation DTCStatusChanged: possible-error=CallbackDTCStatusChange/E_NOT_OK
        arg DTC: type=uint32, direction=IN, server-argument-impl-policy=USE-ARGUMENT-TYPE
        arg DTCStatusOld: type=Dem_UdsStatusByteType, direction=IN, server-argument-impl-policy=USE-ARGUMENT-TYPE
        arg DTCStatusNew: type=Dem_UdsStatusByteType, direction=IN, server-argument-impl-policy=USE-ARGUMENT-TYPE
      error E_NOT_OK: error-code=1
    NvMAdministration: is-service=true
      operation SetBlockProtection: possible-error=NvMAdministration/E_NOT_OK
        arg ProtectionEnabled: type=boolean, direction=IN, server-argument-impl-policy=USE-ARGUMENT-TYPE
      error E_NOT_OK: error-code=1
    NvMService: is-service=true
      operation GetErrorStatus: possible-error=NvMService/E_NOT_OK
        arg ErrorStatus: type=NvM_RequestResultType, direction=OUT, server-argument-impl-policy=USE-ARGUMENT-TYPE
      error E_NOT_OK: error-code=1
    NvSWC_NvMAdministration
      operation SetBlockProtection: possible-error=NvSWC_NvMAdministration/E_NOT_OK
        arg ProtectionEnabled: type=boolean, direction=IN, server-argument-impl-policy=USE-ARGUMENT-TYPE
      error E_NOT_OK: error-code=1
    NvSWC_NvMNotifyInitBlock
      operation InitBlock
    NvSWC_NvMService
      operation GetErrorStatus: possible-error=NvSWC_NvMService/E_NOT_OK
        arg ErrorStatus: type=NvM_RequestResultType, direction=OUT, server-argument-impl-policy=USE-ARGUMENT-TYPE
      error E_NOT_OK: error-code=1
    NvSWC_NvMService_AC2
      operation GetErrorStatus: possible-error=NvSWC_NvMService_AC2/E_NOT_OK
        arg ErrorStatus: type=NvM_RequestResultType, direction=OUT, server-argument-impl-policy=USE-ARGUMENT-TYPE
      operation ReadBlock: possible-error=NvSWC_NvMService_AC2/E_NOT_OK
        arg DstPtr: type=dtRef_VOID, direction=IN, server-argument-impl-policy=USE-ARGUMENT-TYPE
      operation WriteBlock: possible-error=NvSWC_NvMService_AC2/E_NOT_OK
        arg SrcPtr: type=dtRef_const_VOID, direction=IN, server-argument-impl-policy=USE-ARGUMENT-TYPE
      error E_NOT_OK: error-code=1
    NvSWC_NvMService_AC2_SRBS_Defs
      5 x operation, all with possible-error=NvSWC_NvMService_AC2_SRBS_Defs/E_NOT_OK:
        GetErrorStatus
          arg ErrorStatus: type=NvM_RequestResultType, direction=OUT, server-argument-impl-policy=USE-ARGUMENT-TYPE
        ReadBlock
          arg DstPtr: type=dtRef_VOID, direction=IN, server-argument-impl-policy=USE-ARGUMENT-TYPE
        RestoreBlockDefaults
          arg DstPtr: type=dtRef_VOID, direction=IN, server-argument-impl-policy=USE-ARGUMENT-TYPE
        SetRamBlockStatus
          arg RamBlockStatus: type=boolean, direction=IN, server-argument-impl-policy=USE-ARGUMENT-TYPE
        WriteBlock
          arg SrcPtr: type=dtRef_const_VOID, direction=IN, server-argument-impl-policy=USE-ARGUMENT-TYPE
      error E_NOT_OK: error-code=1
